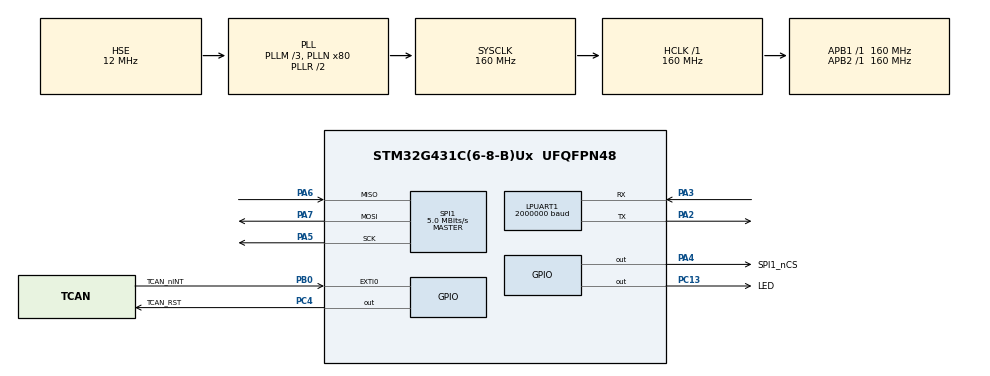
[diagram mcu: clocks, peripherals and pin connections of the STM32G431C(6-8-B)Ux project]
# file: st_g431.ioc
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LPUART1.BaudRate=2000000
Mcu.Family=STM32G4
Mcu.Name=STM32G431C(6-8-B)Ux
Mcu.Package=UFQFPN48
NVIC.EXTI0_IRQn=true\:0\:0\:false\:false\:true\:true\:true\:true
NVIC.PriorityGroup=NVIC_PRIORITYGROUP_4
PA13.Mode=Serial_Wire
PA13.Signal=SYS_JTMS-SWDIO
PA14.Mode=Serial_Wire
PA14.Signal=SYS_JTCK-SWCLK
PA2.Mode=Asynchronous
PA2.Signal=LPUART1_TX
PA3.Mode=Asynchronous
PA3.Signal=LPUART1_RX
PA4.GPIO_Label=SPI1_nCS
PA4.PinState=GPIO_PIN_SET
PA4.Signal=GPIO_Output
PA5.Mode=Full_Duplex_Master
PA5.Signal=SPI1_SCK
PA6.Mode=Full_Duplex_Master
PA6.Signal=SPI1_MISO
PA7.Mode=Full_Duplex_Master
PA7.Signal=SPI1_MOSI
PB0.GPIO_Label=TCAN_nINT
PB0.GPIO_ModeDefaultEXTI=GPIO_MODE_IT_FALLING
PB0.Signal=GPXTI0
PC13.GPIO_Label=LED
PC13.PinState=GPIO_PIN_SET
PC13.Signal=GPIO_Output
PC4.GPIO_Label=TCAN_RST
PC4.PinState=GPIO_PIN_SET
PC4.Signal=GPIO_Output
PF0-OSC_IN.Mode=HSE-External-Oscillator
PF0-OSC_IN.Signal=RCC_OSC_IN
PF1-OSC_OUT.Mode=HSE-External-Oscillator
PF1-OSC_OUT.Signal=RCC_OSC_OUT
ProjectManager.HeapSize=0x200
ProjectManager.StackSize=0x400
ProjectManager.TargetToolchain=MDK-ARM V5.32
RCC.ADC12Freq_Value=160000000
RCC.AHBFreq_Value=160000000
RCC.APB1Freq_Value=160000000
RCC.APB1TimFreq_Value=160000000
RCC.APB2Freq_Value=160000000
RCC.APB2TimFreq_Value=160000000
RCC.CortexFreq_Value=160000000
RCC.EXTERNAL_CLOCK_VALUE=12288000
RCC.HCLKFreq_Value=160000000
RCC.HSE_VALUE=12000000
RCC.HSI48_VALUE=48000000
RCC.HSI_VALUE=16000000
RCC.LSE_VALUE=32768
RCC.PLLM=RCC_PLLM_DIV3
RCC.PLLN=80
RCC.PLLSourceVirtual=RCC_PLLSOURCE_HSE
RCC.SYSCLKFreq_VALUE=160000000
RCC.SYSCLKSource=RCC_SYSCLKSOURCE_PLLCLK
RCC.USBFreq_Value=160000000
RCC.VCOOutputFreq_Value=320000000
SPI1.BaudRatePrescaler=SPI_BAUDRATEPRESCALER_32
SPI1.CalculateBaudRate=5.0 MBits/s
SPI1.DataSize=SPI_DATASIZE_8BIT
SPI1.Direction=SPI_DIRECTION_2LINES
SPI1.Mode=SPI_MODE_MASTER
SPI1.VirtualType=VM_MASTER
VP_SYS_VS_DBSignals.Mode=DisableDeadBatterySignals
board=custom

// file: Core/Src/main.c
/* USER CODE BEGIN Header */
/**
  ******************************************************************************
  * @file           : main.c
  * @brief          : Main program body
  ******************************************************************************
  * @attention
  *
  * Copyright (c) 2025 STMicroelectronics.
  * All rights reserved.
  *
  * This software is licensed under terms that can be found in the LICENSE file
  * in the root directory of this software component.
  * If no LICENSE file comes with this software, it is provided AS-IS.
  *
  ******************************************************************************
  */
/* USER CODE END Header */
#include "main.h"
#include "usart.h"
#include "spi.h"
#include "gpio.h"

/* USER CODE BEGIN Includes */
#include "bsp_uart.h"
#include "bsp_tcan4x5x.h"
/* USER CODE END Includes */

void SystemClock_Config(void);

int main(void)
{

  /* MCU Configuration--------------------------------------------------------*/

  /* Reset of all peripherals, Initializes the Flash interface and the Systick. */
  HAL_Init();

  /* Configure the system clock */
  SystemClock_Config();

  /* Initialize all configured peripherals */
  MX_GPIO_Init();
  MX_LPUART1_UART_Init();
  MX_SPI1_Init();
  /* USER CODE BEGIN 2 */
  // bsp_uart_init();
  __HAL_SPI_ENABLE(&hspi1);
  // HAL_NVIC_EnableIRQ(EXTI0_IRQn);
  bsp_tcan4x5x_init();
  /* USER CODE END 2 */

  /* Infinite loop */
  /* USER CODE BEGIN WHILE */
  // int cnt = 0;
  while (1)
  {
    /* USER CODE END WHILE */

    /* USER CODE BEGIN 3 */
    bsp_tcan4x5x_process();

    // HAL_GPIO_TogglePin(LED_GPIO_Port, LED_Pin);
    // HAL_UART_Transmit(&hlpuart1, (uint8_t *)"Hello, World!\r\n", 15, 1000);
    // print("cnt = %d\r\n", cnt++);
    // HAL_Delay(1000);
    // uint32_t status = bsp_tcan4x5x_read_32(0x000C);
    // print("TCAN4x5x Device Status: 0x%08X\n", status);
  }
  /* USER CODE END 3 */
}

void SystemClock_Config(void)
{
  RCC_OscInitTypeDef RCC_OscInitStruct = {0};
  RCC_ClkInitTypeDef RCC_ClkInitStruct = {0};

  /** Configure the main internal regulator output voltage
  */
  HAL_PWREx_ControlVoltageScaling(PWR_REGULATOR_VOLTAGE_SCALE1_BOOST);

  /** Initializes the RCC Oscillators according to the specified parameters
  * in the RCC_OscInitTypeDef structure.
  */
  RCC_OscInitStruct.OscillatorType = RCC_OSCILLATORTYPE_HSE;
  RCC_OscInitStruct.HSEState = RCC_HSE_ON;
  RCC_OscInitStruct.PLL.PLLState = RCC_PLL_ON;
  RCC_OscInitStruct.PLL.PLLSource = RCC_PLLSOURCE_HSE;
  RCC_OscInitStruct.PLL.PLLM = RCC_PLLM_DIV3;
  RCC_OscInitStruct.PLL.PLLN = 80;
  RCC_OscInitStruct.PLL.PLLP = RCC_PLLP_DIV2;
  RCC_OscInitStruct.PLL.PLLQ = RCC_PLLQ_DIV2;
  RCC_OscInitStruct.PLL.PLLR = RCC_PLLR_DIV2;
  if (HAL_RCC_OscConfig(&RCC_OscInitStruct) != HAL_OK)
  {
    Error_Handler();
  }

  /** Initializes the CPU, AHB and APB buses clocks
  */
  RCC_ClkInitStruct.ClockType = RCC_CLOCKTYPE_HCLK|RCC_CLOCKTYPE_SYSCLK
                              |RCC_CLOCKTYPE_PCLK1|RCC_CLOCKTYPE_PCLK2;
  RCC_ClkInitStruct.SYSCLKSource = RCC_SYSCLKSOURCE_PLLCLK;
  RCC_ClkInitStruct.AHBCLKDivider = RCC_SYSCLK_DIV1;
  RCC_ClkInitStruct.APB1CLKDivider = RCC_HCLK_DIV1;
  RCC_ClkInitStruct.APB2CLKDivider = RCC_HCLK_DIV1;

  if (HAL_RCC_ClockConfig(&RCC_ClkInitStruct, FLASH_LATENCY_4) != HAL_OK)
  {
    Error_Handler();
  }
}

void Error_Handler(void)
{
  __disable_irq();
  while (1)
  {
  }
}
